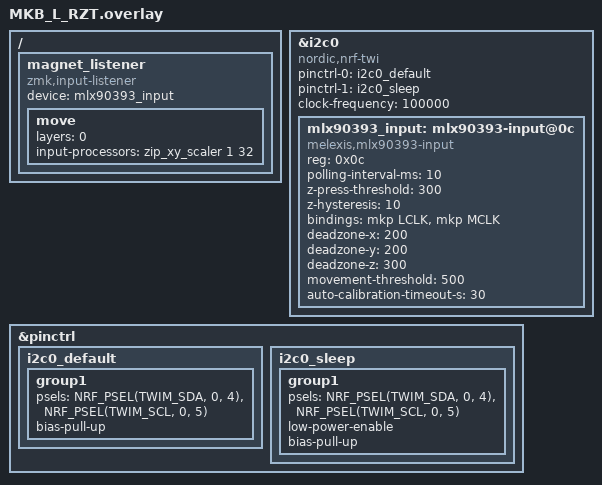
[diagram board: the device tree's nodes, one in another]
#include "MKB_L_Base.dtsi"
#include <dt-bindings/zmk/keys.h>
#include <dt-bindings/zmk/pointing.h>

&i2c0 {
    status = "okay";
    compatible = "nordic,nrf-twi";
    pinctrl-0 = <&i2c0_default>;
    pinctrl-1 = <&i2c0_sleep>;
    pinctrl-names = "default", "sleep";
    clock-frequency = <100000>; 
    
    mlx90393_input: mlx90393-input@0c {
        compatible = "melexis,mlx90393-input";
        reg = <0x0c>;
        
        polling-interval-ms = <10>;
        z-press-threshold = <300>;
        z-hysteresis = <10>;
        
        bindings = <&mkp LCLK>, <&mkp MCLK>;
        
        deadzone-x = <200>;
        deadzone-y = <200>;
        deadzone-z = <300>;
        
        movement-threshold = <500>;
        auto-calibration-timeout-s = <30>;
    };
};

&pinctrl {    
    i2c0_default: i2c0_default {
        group1 {
            psels = <NRF_PSEL(TWIM_SDA, 0,  4)>,
                    <NRF_PSEL(TWIM_SCL, 0,  5)>;
            bias-pull-up;
        };
    };
      
    i2c0_sleep: i2c0_sleep {
        group1 {
            psels = <NRF_PSEL(TWIM_SDA, 0,  4)>,
                    <NRF_PSEL(TWIM_SCL, 0,  5)>;
            low-power-enable;
            bias-pull-up;
        };
    };
};

/ {
    magnet_listener: magnet_listener {
        compatible = "zmk,input-listener";
        status = "okay";
        device = <&mlx90393_input>;
        move {
            layers = <0>;
            input-processors = 
                                // <&zip_xy_transform (INPUT_TRANSFORM_XY_SWAP)>,
                                <&zip_xy_scaler 1 32>;
        };
    };
};
